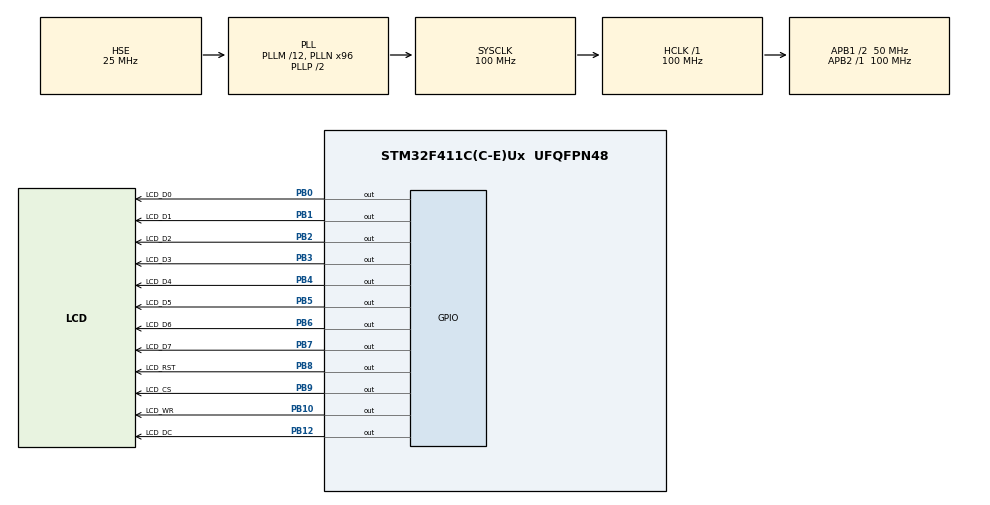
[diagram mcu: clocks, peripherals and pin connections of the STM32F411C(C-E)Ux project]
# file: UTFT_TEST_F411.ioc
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Mcu.Family=STM32F4
Mcu.Name=STM32F411C(C-E)Ux
Mcu.Package=UFQFPN48
NVIC.PriorityGroup=NVIC_PRIORITYGROUP_4
PA13.Mode=Serial_Wire
PA13.Signal=SYS_JTMS-SWDIO
PA14.Mode=Serial_Wire
PA14.Signal=SYS_JTCK-SWCLK
PB0.GPIO_Label=LCD_D0
PB0.Signal=GPIO_Output
PB1.GPIO_Label=LCD_D1
PB1.Signal=GPIO_Output
PB10.GPIO_Label=LCD_WR
PB10.Signal=GPIO_Output
PB12.GPIO_Label=LCD_DC
PB12.Signal=GPIO_Output
PB2.GPIO_Label=LCD_D2
PB2.Signal=GPIO_Output
PB3.GPIO_Label=LCD_D3
PB3.Signal=GPIO_Output
PB4.GPIO_Label=LCD_D4
PB4.Signal=GPIO_Output
PB5.GPIO_Label=LCD_D5
PB5.Signal=GPIO_Output
PB6.GPIO_Label=LCD_D6
PB6.Signal=GPIO_Output
PB7.GPIO_Label=LCD_D7
PB7.Signal=GPIO_Output
PB8.GPIO_Label=LCD_RST
PB8.Signal=GPIO_Output
PB9.GPIO_Label=LCD_CS
PB9.Signal=GPIO_Output
PH0\ -\ OSC_IN.Mode=HSE-External-Oscillator
PH0\ -\ OSC_IN.Signal=RCC_OSC_IN
PH1\ -\ OSC_OUT.Mode=HSE-External-Oscillator
PH1\ -\ OSC_OUT.Signal=RCC_OSC_OUT
ProjectManager.HeapSize=0x200
ProjectManager.StackSize=0x400
ProjectManager.TargetToolchain=EWARM V8
RCC.48MHZClocksFreq_Value=50000000
RCC.AHBFreq_Value=100000000
RCC.APB1CLKDivider=RCC_HCLK_DIV2
RCC.APB1Freq_Value=50000000
RCC.APB1TimFreq_Value=100000000
RCC.APB2Freq_Value=100000000
RCC.APB2TimFreq_Value=100000000
RCC.CortexFreq_Value=100000000
RCC.HCLKFreq_Value=100000000
RCC.HSE_VALUE=25000000
RCC.HSI_VALUE=16000000
RCC.LSE_VALUE=32768
RCC.PLLM=12
RCC.PLLN=96
RCC.PLLSourceVirtual=RCC_PLLSOURCE_HSE
RCC.SYSCLKFreq_VALUE=100000000
RCC.SYSCLKSource=RCC_SYSCLKSOURCE_PLLCLK
RCC.VCOOutputFreq_Value=200000000
board=custom

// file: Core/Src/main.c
/* USER CODE BEGIN Header */
/**
  ******************************************************************************
  * @file           : main.c
  * @brief          : Main program body
  ******************************************************************************
  * @attention
  *
  * <h2><center>&copy; Copyright (c) 2022 STMicroelectronics.
  * All rights reserved.</center></h2>
  *
  * This software component is licensed by ST under BSD 3-Clause license,
  * the "License"; You may not use this file except in compliance with the
  * License. You may obtain a copy of the License at:
  *                        opensource.org/licenses/BSD-3-Clause
  *
  ******************************************************************************
  */
/* USER CODE END Header */
#include "main.h"

/* USER CODE BEGIN Includes */
#include "UTFT_Demo.hpp"
/* USER CODE END Includes */

void SystemClock_Config(void);
static void MX_GPIO_Init(void);

int main(void)
{

  /* MCU Configuration--------------------------------------------------------*/

  /* Reset of all peripherals, Initializes the Flash interface and the Systick. */
  HAL_Init();

  /* Configure the system clock */
  SystemClock_Config();

  /* Initialize all configured peripherals */
  MX_GPIO_Init();
  /* USER CODE BEGIN 2 */
  setup();
  /* USER CODE END 2 */

  /* Infinite loop */
  /* USER CODE BEGIN WHILE */
  while (1)
  {
    loop();
    /* USER CODE END WHILE */

  }
}

void SystemClock_Config(void)
{
  RCC_OscInitTypeDef RCC_OscInitStruct = {0};
  RCC_ClkInitTypeDef RCC_ClkInitStruct = {0};

  /** Configure the main internal regulator output voltage
  */
  __HAL_RCC_PWR_CLK_ENABLE();
  __HAL_PWR_VOLTAGESCALING_CONFIG(PWR_REGULATOR_VOLTAGE_SCALE1);
  /** Initializes the RCC Oscillators according to the specified parameters
  * in the RCC_OscInitTypeDef structure.
  */
  RCC_OscInitStruct.OscillatorType = RCC_OSCILLATORTYPE_HSE;
  RCC_OscInitStruct.HSEState = RCC_HSE_ON;
  RCC_OscInitStruct.PLL.PLLState = RCC_PLL_ON;
  RCC_OscInitStruct.PLL.PLLSource = RCC_PLLSOURCE_HSE;
  RCC_OscInitStruct.PLL.PLLM = 12;
  RCC_OscInitStruct.PLL.PLLN = 96;
  RCC_OscInitStruct.PLL.PLLP = RCC_PLLP_DIV2;
  RCC_OscInitStruct.PLL.PLLQ = 4;
  if (HAL_RCC_OscConfig(&RCC_OscInitStruct) != HAL_OK)
  {
    Error_Handler();
  }
  /** Initializes the CPU, AHB and APB buses clocks
  */
  RCC_ClkInitStruct.ClockType = RCC_CLOCKTYPE_HCLK|RCC_CLOCKTYPE_SYSCLK
                              |RCC_CLOCKTYPE_PCLK1|RCC_CLOCKTYPE_PCLK2;
  RCC_ClkInitStruct.SYSCLKSource = RCC_SYSCLKSOURCE_PLLCLK;
  RCC_ClkInitStruct.AHBCLKDivider = RCC_SYSCLK_DIV1;
  RCC_ClkInitStruct.APB1CLKDivider = RCC_HCLK_DIV2;
  RCC_ClkInitStruct.APB2CLKDivider = RCC_HCLK_DIV1;

  if (HAL_RCC_ClockConfig(&RCC_ClkInitStruct, FLASH_LATENCY_3) != HAL_OK)
  {
    Error_Handler();
  }
}

static void MX_GPIO_Init(void)
{
  GPIO_InitTypeDef GPIO_InitStruct = {0};

  /* GPIO Ports Clock Enable */
  __HAL_RCC_GPIOH_CLK_ENABLE();
  __HAL_RCC_GPIOB_CLK_ENABLE();
  __HAL_RCC_GPIOA_CLK_ENABLE();

  /*Configure GPIO pin Output Level */
  HAL_GPIO_WritePin(GPIOB, LCD_D0_Pin|LCD_D1_Pin|LCD_D2_Pin|LCD_WR_Pin
                          |LCD_DC_Pin|LCD_D3_Pin|LCD_D4_Pin|LCD_D5_Pin
                          |LCD_D6_Pin|LCD_D7_Pin|LCD_RST_Pin|LCD_CS_Pin, GPIO_PIN_RESET);

  /*Configure GPIO pins : LCD_D0_Pin LCD_D1_Pin LCD_D2_Pin LCD_WR_Pin
                           LCD_DC_Pin LCD_D3_Pin LCD_D4_Pin LCD_D5_Pin
                           LCD_D6_Pin LCD_D7_Pin LCD_RST_Pin LCD_CS_Pin */
  GPIO_InitStruct.Pin = LCD_D0_Pin|LCD_D1_Pin|LCD_D2_Pin|LCD_WR_Pin
                          |LCD_DC_Pin|LCD_D3_Pin|LCD_D4_Pin|LCD_D5_Pin
                          |LCD_D6_Pin|LCD_D7_Pin|LCD_RST_Pin|LCD_CS_Pin;
  GPIO_InitStruct.Mode = GPIO_MODE_OUTPUT_PP;
  GPIO_InitStruct.Pull = GPIO_NOPULL;
  GPIO_InitStruct.Speed = GPIO_SPEED_FREQ_LOW;
  HAL_GPIO_Init(GPIOB, &GPIO_InitStruct);

}

void Error_Handler(void)
{
  __disable_irq();
  while (1)
  {
  }
}

/************************ (C) COPYRIGHT STMicroelectronics *****END OF FILE****/
